# ioam3358 register map
Registers are 32-bit, access not given, no defined reset value unless marked. A register's access mark holds for its fields unless they carry their own. Addresses are absolute; registers are grouped by the start of their names; [hi:lo] are bit positions; {n}, {i} and the like mark numbered series.

## CMD0
0x44E1201C CMD0_REG_PHY_CTRL_SLAVE_RATIO_0
  [9:0] CMD_SLAVE_RATIO
0x44E12028 CMD0_REG_PHY_DLL_LOCK_DIFF_0
  [3:0] DLL_LOCK_DIFF
0x44E1202C CMD0_REG_PHY_INVERT_CLKOUT_0
  [0] INVERT_CLK_SEL

## CMD1
0x44E12050 CMD1_REG_PHY_CTRL_SLAVE_RATIO_0
  [9:0] CMD_SLAVE_RATIO
0x44E1205C CMD1_REG_PHY_DLL_LOCK_DIFF_0
  [3:0] DLL_LOCK_DIFF
0x44E12060 CMD1_REG_PHY_INVERT_CLKOUT_0
  [0] INVERT_CLK_SEL

## CMD2
0x44E12084 CMD2_REG_PHY_CTRL_SLAVE_RATIO_0
  [9:0] CMD_SLAVE_RATIO
0x44E12090 CMD2_REG_PHY_DLL_LOCK_DIFF_0
  [3:0] DLL_LOCK_DIFF
0x44E12094 CMD2_REG_PHY_INVERT_CLKOUT_0
  [0] INVERT_CLK_SEL

## DATA0
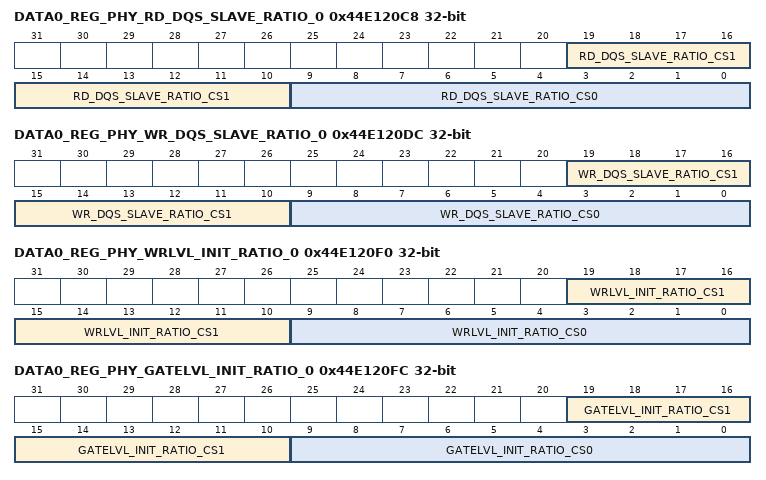
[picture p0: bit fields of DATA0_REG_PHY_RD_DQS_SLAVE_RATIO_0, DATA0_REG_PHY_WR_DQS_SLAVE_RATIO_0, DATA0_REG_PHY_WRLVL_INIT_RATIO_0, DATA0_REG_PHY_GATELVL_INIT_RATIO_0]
0x44E120C8 DATA0_REG_PHY_RD_DQS_SLAVE_RATIO_0
  [19:10] RD_DQS_SLAVE_RATIO_CS1, [9:0] RD_DQS_SLAVE_RATIO_CS0
0x44E120DC DATA0_REG_PHY_WR_DQS_SLAVE_RATIO_0
  [19:10] WR_DQS_SLAVE_RATIO_CS1, [9:0] WR_DQS_SLAVE_RATIO_CS0
0x44E120F0 DATA0_REG_PHY_WRLVL_INIT_RATIO_0
  [19:10] WRLVL_INIT_RATIO_CS1, [9:0] WRLVL_INIT_RATIO_CS0
0x44E120F8 DATA0_REG_PHY_WRLVL_INIT_MODE_0
  [0] WRLVL_INIT_MODE_SEL
0x44E120FC DATA0_REG_PHY_GATELVL_INIT_RATIO_0
  [19:10] GATELVL_INIT_RATIO_CS1, [9:0] GATELVL_INIT_RATIO_CS0
0x44E12104 DATA0_REG_PHY_GATELVL_INIT_MODE_0
  [0] GATELVL_INIT_MODE_SEL
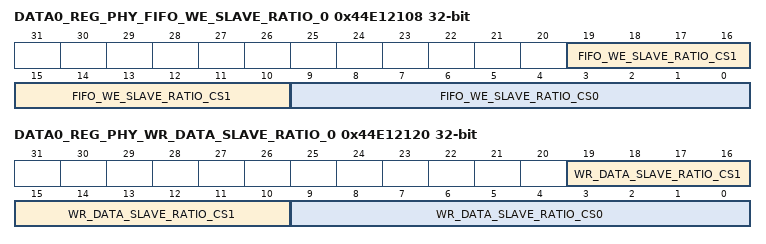
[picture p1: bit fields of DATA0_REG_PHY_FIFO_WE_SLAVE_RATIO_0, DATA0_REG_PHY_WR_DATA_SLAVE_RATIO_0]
0x44E12108 DATA0_REG_PHY_FIFO_WE_SLAVE_RATIO_0
  [19:10] FIFO_WE_SLAVE_RATIO_CS1, [9:0] FIFO_WE_SLAVE_RATIO_CS0
0x44E1211C DATA0_REG_PHY_DQ_OFFSET_0
0x44E12120 DATA0_REG_PHY_WR_DATA_SLAVE_RATIO_0
  [19:10] WR_DATA_SLAVE_RATIO_CS1, [9:0] WR_DATA_SLAVE_RATIO_CS0
0x44E12134 DATA0_REG_PHY_USE_RANK0_DELAYS
  [0] RANK0_DELAY
0x44E12138 DATA0_REG_PHY_DLL_LOCK_DIFF_0

## DATA1
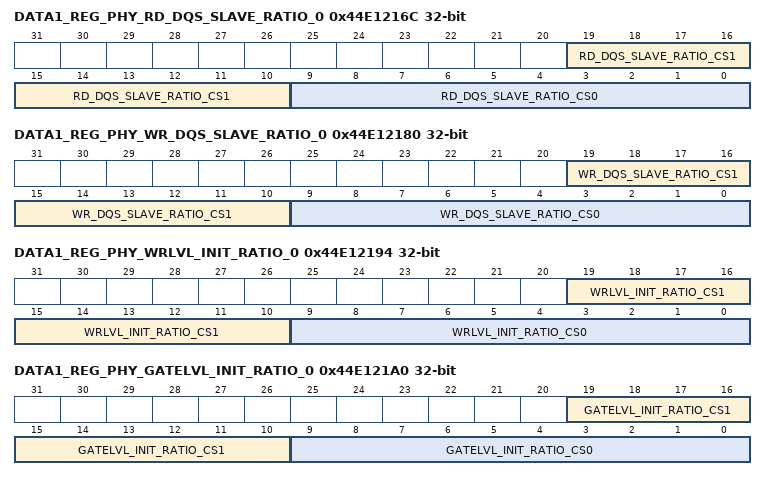
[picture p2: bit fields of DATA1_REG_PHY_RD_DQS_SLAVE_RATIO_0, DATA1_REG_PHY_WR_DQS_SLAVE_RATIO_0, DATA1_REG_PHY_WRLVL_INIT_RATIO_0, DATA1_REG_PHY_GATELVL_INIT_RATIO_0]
0x44E1216C DATA1_REG_PHY_RD_DQS_SLAVE_RATIO_0
  [19:10] RD_DQS_SLAVE_RATIO_CS1, [9:0] RD_DQS_SLAVE_RATIO_CS0
0x44E12180 DATA1_REG_PHY_WR_DQS_SLAVE_RATIO_0
  [19:10] WR_DQS_SLAVE_RATIO_CS1, [9:0] WR_DQS_SLAVE_RATIO_CS0
0x44E12194 DATA1_REG_PHY_WRLVL_INIT_RATIO_0
  [19:10] WRLVL_INIT_RATIO_CS1, [9:0] WRLVL_INIT_RATIO_CS0
0x44E1219C DATA1_REG_PHY_WRLVL_INIT_MODE_0
  [0] WRLVL_INIT_MODE_SEL
0x44E121A0 DATA1_REG_PHY_GATELVL_INIT_RATIO_0
  [19:10] GATELVL_INIT_RATIO_CS1, [9:0] GATELVL_INIT_RATIO_CS0
0x44E121A8 DATA1_REG_PHY_GATELVL_INIT_MODE_0
  [0] GATELVL_INIT_MODE_SEL
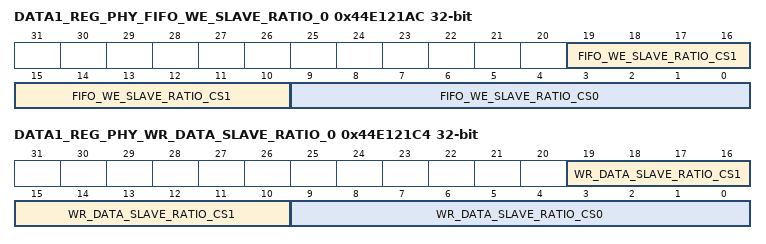
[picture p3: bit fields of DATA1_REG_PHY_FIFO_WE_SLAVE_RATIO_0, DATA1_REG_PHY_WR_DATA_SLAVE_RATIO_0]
0x44E121AC DATA1_REG_PHY_FIFO_WE_SLAVE_RATIO_0
  [19:10] FIFO_WE_SLAVE_RATIO_CS1, [9:0] FIFO_WE_SLAVE_RATIO_CS0
0x44E121C0 DATA1_REG_PHY_DQ_OFFSET_0
0x44E121C4 DATA1_REG_PHY_WR_DATA_SLAVE_RATIO_0
  [19:10] WR_DATA_SLAVE_RATIO_CS1, [9:0] WR_DATA_SLAVE_RATIO_CS0
0x44E121D8 DATA1_REG_PHY_USE_RANK0_DELAYS
  [0] RANK0_DELAY
0x44E121DC DATA1_REG_PHY_DLL_LOCK_DIFF_0

## ELM
0x48080000 ELM_REVISION
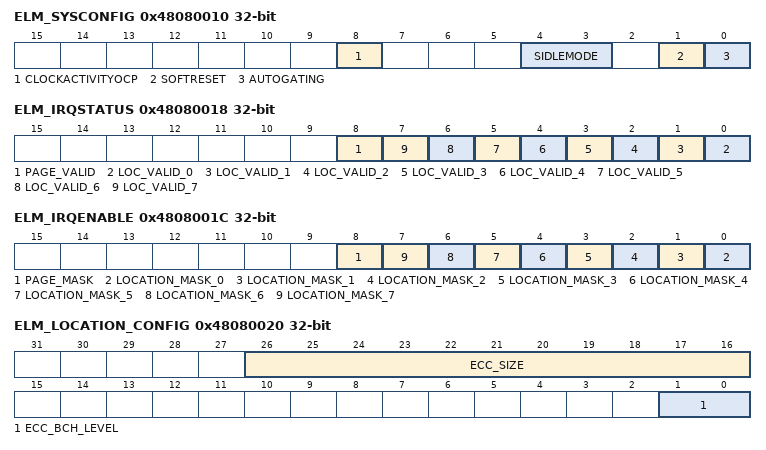
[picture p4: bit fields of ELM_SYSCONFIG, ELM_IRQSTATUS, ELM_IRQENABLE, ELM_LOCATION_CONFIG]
0x48080010 ELM_SYSCONFIG
  [8] CLOCKACTIVITYOCP, [4:3] SIDLEMODE, [1] SOFTRESET, [0] AUTOGATING
0x48080014 ELM_SYSSTATUS
  [0] RESETDONE
0x48080018 ELM_IRQSTATUS
  [8] PAGE_VALID, [n] LOC_VALID_{n} (n=0..7)
0x4808001C ELM_IRQENABLE
  [8] PAGE_MASK, [n] LOCATION_MASK_{n} (n=0..7)
0x48080020 ELM_LOCATION_CONFIG
  [26:16] ECC_SIZE, [1:0] ECC_BCH_LEVEL
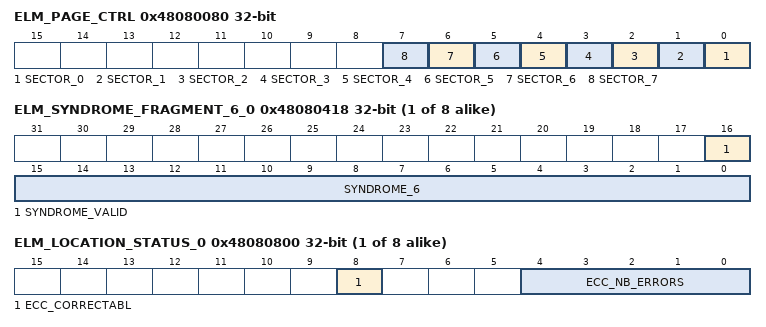
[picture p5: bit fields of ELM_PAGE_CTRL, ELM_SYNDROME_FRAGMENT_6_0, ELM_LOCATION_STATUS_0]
0x48080080 ELM_PAGE_CTRL
  [n] SECTOR_{n} (n=0..7)
{0x48080400+0x40*i} ELM_SYNDROME_FRAGMENT_0_{i} (i=0..7)
  [31:0] SYNDROME_0
{0x48080404+0x40*i} ELM_SYNDROME_FRAGMENT_1_{i} (i=0..7)
  [31:0] SYNDROME_1
{0x48080408+0x40*i} ELM_SYNDROME_FRAGMENT_2_{i} (i=0..7)
  [31:0] SYNDROME_2
{0x4808040C+0x40*i} ELM_SYNDROME_FRAGMENT_3_{i} (i=0..7)
  [31:0] SYNDROME_3
{0x48080410+0x40*i} ELM_SYNDROME_FRAGMENT_4_{i} (i=0..7)
  [31:0] SYNDROME_4
{0x48080414+0x40*i} ELM_SYNDROME_FRAGMENT_5_{i} (i=0..7)
  [31:0] SYNDROME_5
{0x48080418+0x40*i} ELM_SYNDROME_FRAGMENT_6_{i} (i=0..7)
  [16] SYNDROME_VALID, [15:0] SYNDROME_6
{0x48080800+0x100*i} ELM_LOCATION_STATUS_{i} (i=0..7)
  [8] ECC_CORRECTABL, [4:0] ECC_NB_ERRORS
{0x48080880+4i} ELM_ERROR_LOCATION_{i}_0 (i=0..15)
  [12:0] ECC_ERROR_LOCATION
{0x48080980+4i} ELM_ERROR_LOCATION_{i}_1 (i=0..15)
  [12:0] ECC_ERROR_LOCATION
{0x48080A80+4i} ELM_ERROR_LOCATION_{i}_2 (i=0..15)
  [12:0] ECC_ERROR_LOCATION
{0x48080B80+4i} ELM_ERROR_LOCATION_{i}_3 (i=0..15)
  [12:0] ECC_ERROR_LOCATION
{0x48080C80+4i} ELM_ERROR_LOCATION_{i}_4 (i=0..15)
  [12:0] ECC_ERROR_LOCATION
{0x48080D80+4i} ELM_ERROR_LOCATION_{i}_5 (i=0..15)
  [12:0] ECC_ERROR_LOCATION
{0x48080E80+4i} ELM_ERROR_LOCATION_{i}_6 (i=0..15)
  [12:0] ECC_ERROR_LOCATION
{0x48080F80+4i} ELM_ERROR_LOCATION_{i}_7 (i=0..15)
  [12:0] ECC_ERROR_LOCATION
